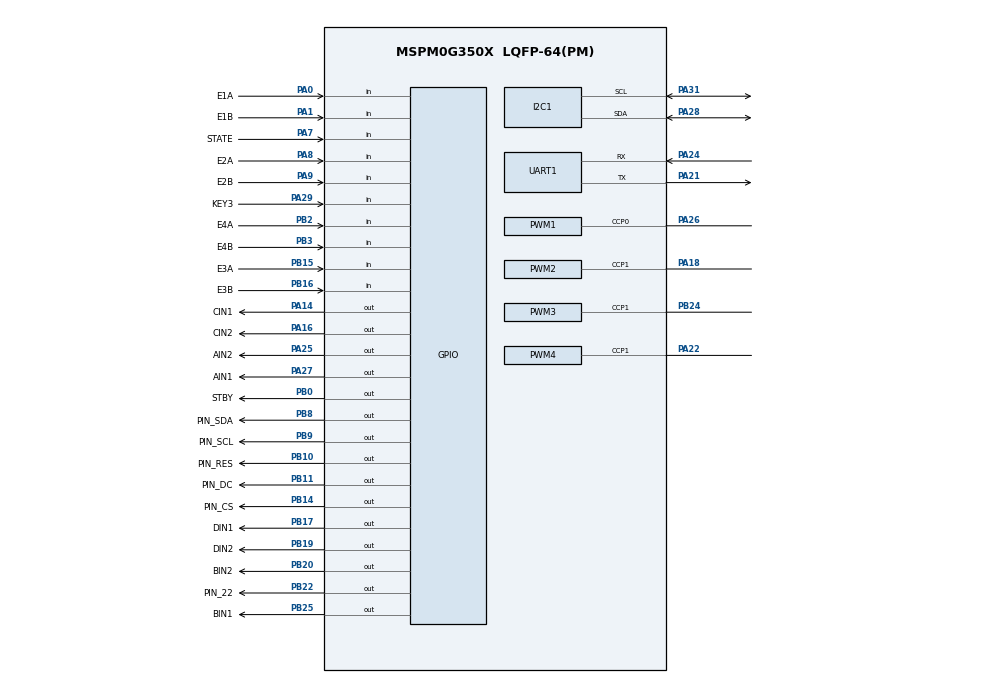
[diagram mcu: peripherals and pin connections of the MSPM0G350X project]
/**
 * @cliArgs --device "MSPM0G350X" --part "Default" --package "LQFP-64(PM)" --product "mspm0_sdk@2.10.00.04"
 * @versions {"tool":"1.26.2+4477"}
 */

/**
 * Import the modules used in this configuration.
 */
const Board  = scripting.addModule("/ti/driverlib/Board");
const GPIO   = scripting.addModule("/ti/driverlib/GPIO", {}, false);
const GPIO1  = GPIO.addInstance();
const GPIO2  = GPIO.addInstance();
const GPIO3  = GPIO.addInstance();
const GPIO4  = GPIO.addInstance();
const GPIO5  = GPIO.addInstance();
const GPIO6  = GPIO.addInstance();
const I2C    = scripting.addModule("/ti/driverlib/I2C", {}, false);
const I2C1   = I2C.addInstance();
const PWM    = scripting.addModule("/ti/driverlib/PWM", {}, false);
const PWM1   = PWM.addInstance();
const PWM2   = PWM.addInstance();
const PWM3   = PWM.addInstance();
const PWM4   = PWM.addInstance();
const SYSCTL = scripting.addModule("/ti/driverlib/SYSCTL");
const TIMER  = scripting.addModule("/ti/driverlib/TIMER", {}, false);
const TIMER1 = TIMER.addInstance();
const UART   = scripting.addModule("/ti/driverlib/UART", {}, false);
const UART1  = UART.addInstance();

/**
 * Write custom configuration values to the imported modules.
 */
const divider6       = system.clockTree["PLL_CLK2X_DIV"];
divider6.divideValue = 4;

const divider7       = system.clockTree["PLL_PDIV"];
divider7.divideValue = 2;

const divider9       = system.clockTree["UDIV"];
divider9.divideValue = 2;

const multiplier2         = system.clockTree["PLL_QDIV"];
multiplier2.multiplyValue = 10;

const mux8       = system.clockTree["HSCLKMUX"];
mux8.inputSelect = "HSCLKMUX_SYSPLL2X";


GPIO1.$name                              = "LED1";
GPIO1.port                               = "PORTB";
GPIO1.associatedPins[0].$name            = "PIN_22";
GPIO1.associatedPins[0].internalResistor = "PULL_DOWN";
GPIO1.associatedPins[0].assignedPin      = "22";
GPIO1.associatedPins[0].pin.$assign      = "PB22";

GPIO2.$name                         = "GPIO_OLED";
GPIO2.associatedPins.create(5);
GPIO2.associatedPins[0].$name       = "PIN_RES";
GPIO2.associatedPins[0].pin.$assign = "PB10";
GPIO2.associatedPins[1].$name       = "PIN_SCL";
GPIO2.associatedPins[1].pin.$assign = "PB9";
GPIO2.associatedPins[2].$name       = "PIN_SDA";
GPIO2.associatedPins[2].pin.$assign = "PB8";
GPIO2.associatedPins[3].$name       = "PIN_DC";
GPIO2.associatedPins[3].pin.$assign = "PB11";
GPIO2.associatedPins[4].$name       = "PIN_CS";
GPIO2.associatedPins[4].pin.$assign = "PB14";

GPIO3.$name                         = "HC05";
GPIO3.port                          = "PORTA";
GPIO3.associatedPins[0].$name       = "STATE";
GPIO3.associatedPins[0].direction   = "INPUT";
GPIO3.associatedPins[0].assignedPin = "7";
GPIO3.associatedPins[0].pin.$assign = "PA7";

GPIO4.$name                               = "KEY";
GPIO4.associatedPins.create(5);
GPIO4.associatedPins[0].$name             = "KEY1";
GPIO4.associatedPins[0].direction         = "INPUT";
GPIO4.associatedPins[0].assignedPort      = "PORTB";
GPIO4.associatedPins[0].assignedPin       = "18";
GPIO4.associatedPins[0].interruptEn       = true;
GPIO4.associatedPins[0].polarity          = "RISE";
GPIO4.associatedPins[1].direction         = "INPUT";
GPIO4.associatedPins[1].interruptEn       = true;
GPIO4.associatedPins[1].assignedPort      = "PORTA";
GPIO4.associatedPins[1].assignedPin       = "13";
GPIO4.associatedPins[1].$name             = "KEY2";
GPIO4.associatedPins[1].polarity          = "RISE";
GPIO4.associatedPins[2].$name             = "PB21";
GPIO4.associatedPins[2].direction         = "INPUT";
GPIO4.associatedPins[2].assignedPort      = "PORTB";
GPIO4.associatedPins[2].assignedPin       = "21";
GPIO4.associatedPins[2].polarity          = "FALL";
GPIO4.associatedPins[2].interruptEn       = true;
GPIO4.associatedPins[3].direction         = "INPUT";
GPIO4.associatedPins[3].$name             = "KEY4";
GPIO4.associatedPins[3].assignedPort      = "PORTB";
GPIO4.associatedPins[3].assignedPin       = "1";
GPIO4.associatedPins[3].interruptEn       = true;
GPIO4.associatedPins[3].polarity          = "RISE";
GPIO4.associatedPins[4].$name             = "KEY3";
GPIO4.associatedPins[4].direction         = "INPUT";
GPIO4.associatedPins[4].interruptEn       = true;
GPIO4.associatedPins[4].polarity          = "RISE";
GPIO4.associatedPins[4].interruptPriority = "0";
GPIO4.associatedPins[4].pin.$assign       = "PA29";

GPIO5.$name                               = "GPIO_ENCODER";
GPIO5.associatedPins.create(8);
GPIO5.associatedPins[0].$name             = "E1A";
GPIO5.associatedPins[0].direction         = "INPUT";
GPIO5.associatedPins[0].interruptEn       = true;
GPIO5.associatedPins[0].interruptPriority = "0";
GPIO5.associatedPins[0].polarity          = "RISE";
GPIO5.associatedPins[0].pin.$assign       = "PA0";
GPIO5.associatedPins[1].$name             = "E1B";
GPIO5.associatedPins[1].direction         = "INPUT";
GPIO5.associatedPins[1].interruptEn       = true;
GPIO5.associatedPins[1].interruptPriority = "0";
GPIO5.associatedPins[1].polarity          = "RISE";
GPIO5.associatedPins[1].pin.$assign       = "PA1";
GPIO5.associatedPins[2].$name             = "E2A";
GPIO5.associatedPins[2].direction         = "INPUT";
GPIO5.associatedPins[2].polarity          = "RISE";
GPIO5.associatedPins[2].interruptEn       = true;
GPIO5.associatedPins[2].interruptPriority = "0";
GPIO5.associatedPins[2].pin.$assign       = "PA8";
GPIO5.associatedPins[3].$name             = "E2B";
GPIO5.associatedPins[3].direction         = "INPUT";
GPIO5.associatedPins[3].interruptEn       = true;
GPIO5.associatedPins[3].interruptPriority = "0";
GPIO5.associatedPins[3].polarity          = "RISE";
GPIO5.associatedPins[3].pin.$assign       = "PA9";
GPIO5.associatedPins[4].$name             = "E3A";
GPIO5.associatedPins[4].direction         = "INPUT";
GPIO5.associatedPins[4].polarity          = "RISE";
GPIO5.associatedPins[4].interruptEn       = true;
GPIO5.associatedPins[4].interruptPriority = "0";
GPIO5.associatedPins[4].pin.$assign       = "PB15";
GPIO5.associatedPins[5].$name             = "E3B";
GPIO5.associatedPins[5].direction         = "INPUT";
GPIO5.associatedPins[5].polarity          = "RISE";
GPIO5.associatedPins[5].interruptEn       = true;
GPIO5.associatedPins[5].interruptPriority = "0";
GPIO5.associatedPins[5].pin.$assign       = "PB16";
GPIO5.associatedPins[6].$name             = "E4A";
GPIO5.associatedPins[6].direction         = "INPUT";
GPIO5.associatedPins[6].interruptEn       = true;
GPIO5.associatedPins[6].polarity          = "RISE";
GPIO5.associatedPins[6].interruptPriority = "0";
GPIO5.associatedPins[6].pin.$assign       = "PB2";
GPIO5.associatedPins[7].$name             = "E4B";
GPIO5.associatedPins[7].direction         = "INPUT";
GPIO5.associatedPins[7].polarity          = "RISE";
GPIO5.associatedPins[7].interruptEn       = true;
GPIO5.associatedPins[7].interruptPriority = "0";
GPIO5.associatedPins[7].pin.$assign       = "PB3";

GPIO6.$name                         = "GPIO_MOTOR";
GPIO6.associatedPins.create(9);
GPIO6.associatedPins[0].$name       = "AIN1";
GPIO6.associatedPins[0].pin.$assign = "PA27";
GPIO6.associatedPins[1].$name       = "AIN2";
GPIO6.associatedPins[1].pin.$assign = "PA25";
GPIO6.associatedPins[2].$name       = "BIN1";
GPIO6.associatedPins[2].pin.$assign = "PB25";
GPIO6.associatedPins[3].$name       = "BIN2";
GPIO6.associatedPins[3].pin.$assign = "PB20";
GPIO6.associatedPins[4].$name       = "CIN1";
GPIO6.associatedPins[4].pin.$assign = "PA14";
GPIO6.associatedPins[5].$name       = "CIN2";
GPIO6.associatedPins[5].pin.$assign = "PA16";
GPIO6.associatedPins[6].$name       = "DIN1";
GPIO6.associatedPins[6].pin.$assign = "PB17";
GPIO6.associatedPins[7].$name       = "DIN2";
GPIO6.associatedPins[7].pin.$assign = "PB19";
GPIO6.associatedPins[8].$name       = "STBY";
GPIO6.associatedPins[8].pin.$assign = "PB0";

I2C1.$name                             = "I2C_BUS";
I2C1.basicEnableController             = true;
I2C1.basicControllerStandardBusSpeed   = "Fast";
I2C1.peripheral.sdaPin.$assign         = "PA28";
I2C1.peripheral.sclPin.$assign         = "PA31";
I2C1.sdaPinConfig.hideOutputInversion  = scripting.forceWrite(false);
I2C1.sdaPinConfig.onlyInternalResistor = scripting.forceWrite(false);
I2C1.sdaPinConfig.passedPeripheralType = scripting.forceWrite("Digital");
I2C1.sdaPinConfig.$name                = "ti_driverlib_gpio_GPIOPinGeneric5";
I2C1.sclPinConfig.hideOutputInversion  = scripting.forceWrite(false);
I2C1.sclPinConfig.onlyInternalResistor = scripting.forceWrite(false);
I2C1.sclPinConfig.passedPeripheralType = scripting.forceWrite("Digital");
I2C1.sclPinConfig.$name                = "ti_driverlib_gpio_GPIOPinGeneric6";

PWM1.$name                              = "PWMA";
PWM1.clockDivider                       = 4;
PWM1.timerStartTimer                    = true;
PWM1.ccIndex                            = [0];
PWM1.PWM_CHANNEL_0.$name                = "ti_driverlib_pwm_PWMTimerCC0";
PWM1.PWM_CHANNEL_0.initVal              = "HIGH";
PWM1.ccp0PinConfig.$name                = "ti_driverlib_gpio_GPIOPinGeneric2";
PWM1.ccp0PinConfig.direction            = scripting.forceWrite("OUTPUT");
PWM1.ccp0PinConfig.hideOutputInversion  = scripting.forceWrite(false);
PWM1.ccp0PinConfig.onlyInternalResistor = scripting.forceWrite(false);
PWM1.ccp0PinConfig.passedPeripheralType = scripting.forceWrite("Digital");
PWM1.peripheral.$assign                 = "TIMG8";
PWM1.peripheral.ccp0Pin.$assign         = "PA26";

PWM2.$name                              = "PWMB";
PWM2.clockDivider                       = 8;
PWM2.ccIndex                            = [1];
PWM2.timerStartTimer                    = true;
PWM2.ccp1PinConfig.direction            = scripting.forceWrite("OUTPUT");
PWM2.ccp1PinConfig.hideOutputInversion  = scripting.forceWrite(false);
PWM2.ccp1PinConfig.onlyInternalResistor = scripting.forceWrite(false);
PWM2.ccp1PinConfig.passedPeripheralType = scripting.forceWrite("Digital");
PWM2.ccp1PinConfig.$name                = "ti_driverlib_gpio_GPIOPinGeneric3";
PWM2.peripheral.$assign                 = "TIMG7";
PWM2.peripheral.ccp1Pin.$assign         = "PA18";
PWM2.PWM_CHANNEL_1.$name                = "ti_driverlib_pwm_PWMTimerCC1";
PWM2.PWM_CHANNEL_1.initVal              = "HIGH";

PWM3.$name                              = "PWMC";
PWM3.clockDivider                       = 8;
PWM3.ccIndex                            = [1];
PWM3.timerStartTimer                    = true;
PWM3.ccp1PinConfig.direction            = scripting.forceWrite("OUTPUT");
PWM3.ccp1PinConfig.hideOutputInversion  = scripting.forceWrite(false);
PWM3.ccp1PinConfig.onlyInternalResistor = scripting.forceWrite(false);
PWM3.ccp1PinConfig.passedPeripheralType = scripting.forceWrite("Digital");
PWM3.ccp1PinConfig.$name                = "ti_driverlib_gpio_GPIOPinGeneric4";
PWM3.peripheral.$assign                 = "TIMG12";
PWM3.peripheral.ccp1Pin.$assign         = "PB24";
PWM3.PWM_CHANNEL_1.$name                = "ti_driverlib_pwm_PWMTimerCC2";
PWM3.PWM_CHANNEL_1.initVal              = "HIGH";

PWM4.$name                              = "PWMD";
PWM4.clockDivider                       = 8;
PWM4.timerStartTimer                    = true;
PWM4.ccIndex                            = [1];
PWM4.ccp1PinConfig.direction            = scripting.forceWrite("OUTPUT");
PWM4.ccp1PinConfig.hideOutputInversion  = scripting.forceWrite(false);
PWM4.ccp1PinConfig.onlyInternalResistor = scripting.forceWrite(false);
PWM4.ccp1PinConfig.passedPeripheralType = scripting.forceWrite("Digital");
PWM4.ccp1PinConfig.$name                = "ti_driverlib_gpio_GPIOPinGeneric8";
PWM4.peripheral.$assign                 = "TIMG6";
PWM4.peripheral.ccp1Pin.$assign         = "PA22";
PWM4.PWM_CHANNEL_1.$name                = "ti_driverlib_pwm_PWMTimerCC3";

SYSCTL.forceDefaultClkConfig = true;
SYSCTL.clockTreeEn           = true;

TIMER1.$name              = "TIMER_TICK";
TIMER1.timerClkDiv        = 8;
TIMER1.timerMode          = "PERIODIC_UP";
TIMER1.timerPeriod        = "20ms";
TIMER1.timerClkPrescale   = 10;
TIMER1.timerStartTimer    = true;
TIMER1.interrupts         = ["ZERO"];
TIMER1.interruptPriority  = "0";
TIMER1.peripheral.$assign = "TIMG0";

UART1.$name                            = "UART_2";
UART1.rxFifoThreshold                  = "DL_UART_RX_FIFO_LEVEL_ONE_ENTRY";
UART1.enableDMARX                      = false;
UART1.enableDMATX                      = false;
UART1.uartClkDiv                       = "4";
UART1.enableFIFO                       = true;
UART1.enabledInterrupts                = ["RX"];
UART1.peripheral.$assign               = "UART2";
UART1.peripheral.rxPin.$assign         = "PA24";
UART1.peripheral.txPin.$assign         = "PA21";
UART1.txPinConfig.direction            = scripting.forceWrite("OUTPUT");
UART1.txPinConfig.hideOutputInversion  = scripting.forceWrite(false);
UART1.txPinConfig.onlyInternalResistor = scripting.forceWrite(false);
UART1.txPinConfig.passedPeripheralType = scripting.forceWrite("Digital");
UART1.txPinConfig.$name                = "ti_driverlib_gpio_GPIOPinGeneric0";
UART1.rxPinConfig.hideOutputInversion  = scripting.forceWrite(false);
UART1.rxPinConfig.onlyInternalResistor = scripting.forceWrite(false);
UART1.rxPinConfig.passedPeripheralType = scripting.forceWrite("Digital");
UART1.rxPinConfig.$name                = "ti_driverlib_gpio_GPIOPinGeneric1";

/**
 * Pinmux solution for unlocked pins/peripherals. This ensures that minor changes to the automatic solver in a future
 * version of the tool will not impact the pinmux you originally saw.  These lines can be completely deleted in order to
 * re-solve from scratch.
 */
Board.peripheral.$suggestSolution            = "DEBUGSS";
Board.peripheral.swclkPin.$suggestSolution   = "PA20";
Board.peripheral.swdioPin.$suggestSolution   = "PA19";
GPIO4.associatedPins[0].pin.$suggestSolution = "PB18";
GPIO4.associatedPins[1].pin.$suggestSolution = "PA13";
GPIO4.associatedPins[2].pin.$suggestSolution = "PB21";
GPIO4.associatedPins[3].pin.$suggestSolution = "PB1";
I2C1.peripheral.$suggestSolution             = "I2C0";
